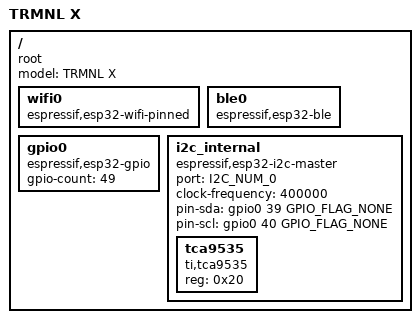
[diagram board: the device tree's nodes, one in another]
/dts-v1/;

#include <tactility/bindings/root.h>
#include <tactility/bindings/esp32_ble.h>
#include <tactility/bindings/esp32_wifi_pinned.h>
#include <tactility/bindings/esp32_gpio.h>
#include <tactility/bindings/esp32_i2c_master.h>
#include <bindings/tca95xx.h>

/ {
	compatible = "root";
	model = "TRMNL X";

	wifi0 {
		compatible = "espressif,esp32-wifi-pinned";
	};

	ble0 {
		compatible = "espressif,esp32-ble";
	};

	gpio0 {
		compatible = "espressif,esp32-gpio";
		gpio-count = <49>;
	};

	i2c_internal {
		compatible = "espressif,esp32-i2c-master";
		port = <I2C_NUM_0>;
		clock-frequency = <400000>;
		pin-sda = <&gpio0 39 GPIO_FLAG_NONE>;
		pin-scl = <&gpio0 40 GPIO_FLAG_NONE>;

		tca9535: tca9535 {
			compatible = "ti,tca9535";
			reg = <0x20>;
		};
	};
};
